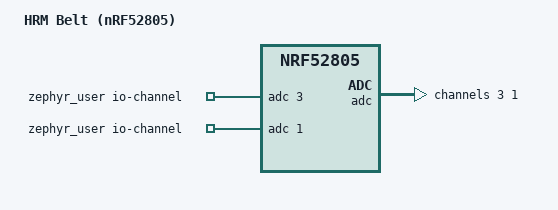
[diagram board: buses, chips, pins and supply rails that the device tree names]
/dts-v1/;
#include <nordic/nrf52805_caaa.dtsi>
#include <zephyr/dt-bindings/adc/adc.h>
#include <zephyr/dt-bindings/adc/nrf-saadc.h>

/ {
	model = "HRM Belt (nRF52805)";
	compatible = "custom,hrm-belt";

	chosen {
		zephyr,sram = &sram0;
		zephyr,flash = &flash0;
		zephyr,code-partition = &slot0_partition;
	};

	/* [0] heartbeat analog input (AIN3/F6); [1] VDD for battery level */
	zephyr_user: zephyr,user {
		io-channels = <&adc 3>, <&adc 1>;
	};
};

&adc {
	status = "okay";
	#address-cells = <1>;
	#size-cells = <0>;

	channel@3 {
		reg = <3>;
		zephyr,gain = "ADC_GAIN_1_4";
		zephyr,reference = "ADC_REF_VDD_1_4";
		zephyr,acquisition-time = <ADC_ACQ_TIME(ADC_ACQ_TIME_MICROSECONDS, 10)>;
		zephyr,input-positive = <NRF_SAADC_AIN3>;   /* AIN3 = P0.05 = ball F6 */
		zephyr,resolution = <12>;
		zephyr,oversampling = <2>;
	};

	/* VDD (battery) measurement: gain 1/6, internal 0.6 V ref -> 0..3.6 V range */
	channel@1 {
		reg = <1>;
		zephyr,gain = "ADC_GAIN_1_6";
		zephyr,reference = "ADC_REF_INTERNAL";
		zephyr,acquisition-time = <ADC_ACQ_TIME(ADC_ACQ_TIME_MICROSECONDS, 20)>;
		zephyr,input-positive = <NRF_SAADC_VDD>;
		zephyr,resolution = <12>;
	};
};

&gpio0    { status = "okay"; };
&gpiote   { status = "okay"; };

/* nRF52805 flash: 192 kB. Single app slot (no MCUboot — we flash via SWD). */
&flash0 {
	partitions {
		compatible = "fixed-partitions";
		#address-cells = <1>;
		#size-cells = <1>;

		slot0_partition: partition@0 {
			label = "image-0";
			reg = <0x00000000 DT_SIZE_K(188)>;
		};
		storage_partition: partition@2f000 {
			label = "storage";
			reg = <0x0002f000 DT_SIZE_K(4)>;
		};
	};
};
